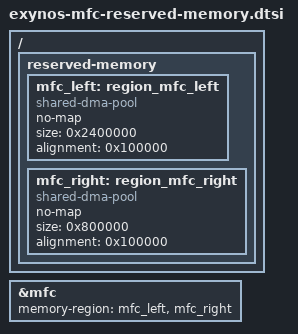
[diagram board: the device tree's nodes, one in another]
// SPDX-License-Identifier: GPL-2.0
/*
 * Samsung's Exynos SoC MFC (Video Codec) reserved memory common definition.
 *
 * Copyright (c) 2016 Samsung Electronics Co., Ltd
 */

/ {
	reserved-memory {
		#address-cells = <1>;
		#size-cells = <1>;
		ranges;

		mfc_left: region_mfc_left {
			compatible = "shared-dma-pool";
			no-map;
			size = <0x2400000>;
			alignment = <0x100000>;
		};

		mfc_right: region_mfc_right {
			compatible = "shared-dma-pool";
			no-map;
			size = <0x800000>;
			alignment = <0x100000>;
		};
	};
};

&mfc {
	memory-region = <&mfc_left>, <&mfc_right>;
};
